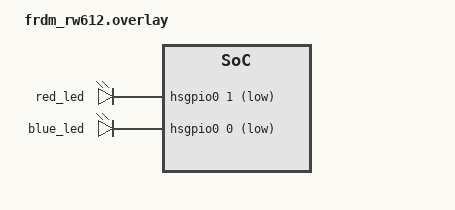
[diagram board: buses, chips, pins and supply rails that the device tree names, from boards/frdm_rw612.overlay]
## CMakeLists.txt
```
cmake_minimum_required(VERSION 3.20.0)

get_filename_component(PROJECT_ROOT ${CMAKE_CURRENT_SOURCE_DIR}/.. ABSOLUTE)
list(APPEND BOARD_ROOT ${PROJECT_ROOT})
find_package(Zephyr REQUIRED)
project(my_zephyr_app)

target_include_directories(app PRIVATE ${CMAKE_CURRENT_SOURCE_DIR})
target_sources(app PRIVATE src/main.cpp)

add_subdirectory(drivers/our_led_sensor)
```

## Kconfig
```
menuconfig APP_HEARTBEAT_PERIOD_MS
	int "Heartbeat Period MS (100-2000)"
	range 100 2000
	default 500
	help
	  Set Heartbeat Period.

menuconfig LED_SUBSYSTEM
	bool "LED Subsystem"
	default y
	help
	  Enable the LED subsystem.

if LED_SUBSYSTEM

choice LED_BLINK_SLEEP_CHOICE
	prompt "LED blink sleep time"
	default LED_BLINK_SLEEP_1S
	help
	  Select the LED blink sleep interval.

config LED_BLINK_SLEEP_250MS
	bool "250ms"

config LED_BLINK_SLEEP_500MS
	bool "500ms"

config LED_BLINK_SLEEP_1S
	bool "1s (medium)"

config LED_BLINK_SLEEP_2S
	bool "2s"

endchoice

config LED_BLINK_SLEEP_MS
	int
	default 250  if LED_BLINK_SLEEP_250MS
	default 500  if LED_BLINK_SLEEP_500MS
	default 1000 if LED_BLINK_SLEEP_1S
	default 2000 if LED_BLINK_SLEEP_2S

menuconfig LED_ADVANCED_SETTINGS
	bool "Advanced LED settings"
	default n
	help
	  Enable advanced LED configuration options.

if LED_ADVANCED_SETTINGS

config LED_BRIGHTNESS
	int "LED brightness (0-100)"
	range 0 100
	default 100
	help
	  Set LED brightness as a percentage.

config LED_FADE_DURATION_MS
	int "LED fade duration (ms)"
	range 0 5000
	default 500
	help
	  Set fade duration in milliseconds.

menu "Expert settings"
	visible if LED_ADVANCED_SETTINGS

config LED_DEBUG
	bool "Enable LED debugging"
	default n

config LED_CUSTOM_BLINK_PATTERN
	bool "Custom blink pattern"
	default n

endmenu

endif # LED_ADVANCED_SETTINGS

endif # LED_SUBSYSTEM

source "Kconfig.zephyr"
rsource "drivers/our_led_sensor/Kconfig"
```

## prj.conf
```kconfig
CONFIG_GPIO=y
CONFIG_LOG=y
CONFIG_OUR_LED_SENSOR=y
CONFIG_SENSOR=y
```

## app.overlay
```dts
#include <zephyr/dt-bindings/gpio/gpio.h>

/{
	aliases {
		app-led = &led0;
	};

    led_sensor0: led_sensor {
        compatible = "our,led-sensor";
        led-gpios = <&gpio0 25 GPIO_ACTIVE_HIGH>; 
        status = "okay";
    };
};
```

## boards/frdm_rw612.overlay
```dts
/{
	leds {

		red_led: led_0 {
			gpios = < &hsgpio0 1 GPIO_ACTIVE_LOW>; 
		};

        blue_led: led_2 {
			gpios = < &hsgpio0 0 GPIO_ACTIVE_LOW>; 
		};
	};
};
```

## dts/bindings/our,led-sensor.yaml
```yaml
description: Our Simple LED Sensor

compatible: "our,led-sensor"

include: base.yaml

properties:
  led-gpios:
    type: phandle-array
    required: true
```

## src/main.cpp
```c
#include <zephyr/device.h>
#include <zephyr/drivers/sensor.h>
#include <zephyr/kernel.h>
#include <zephyr/logging/log.h>
#include "drivers/our_led_sensor/our_led_sensor.h"

#define SLEEP_TIME_MS 1000

#define LED_NODE DT_ALIAS(led0)
#define LED_SENSOR_NODE DT_NODELABEL(led_sensor0)

// static const struct gpio_dt_spec led = GPIO_DT_SPEC_GET(LED_NODE, gpios);

LOG_MODULE_REGISTER(main, LOG_LEVEL_INF);

int main(void)
{
    printk("Hello World! %s\n", CONFIG_BOARD);

    const struct device *dev = DEVICE_DT_GET(LED_SENSOR_NODE);
    struct sensor_value val;

    if (!device_is_ready(dev)) {
        printk("LED sensor device not ready\n");
        return 0;
    }

    // Extension API call
    led_sensor_set_blink_count(dev, 3);

    while (1) {
        sensor_sample_fetch_chan(dev, SENSOR_CHAN_LIGHT);
        sensor_channel_get(dev, SENSOR_CHAN_LIGHT, &val);
        k_msleep(CONFIG_APP_HEARTBEAT_PERIOD_MS);
    }
    return 0;
}
```
